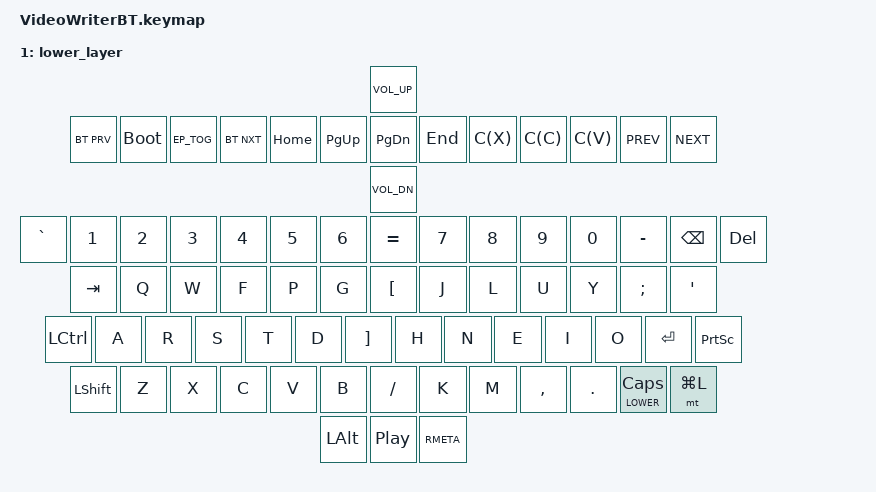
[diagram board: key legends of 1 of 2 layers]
/*
 * Copyright (c) 2020 The ZMK Contributors
 *
 * SPDX-License-Identifier: MIT
 */

#include <behaviors.dtsi>
#include <dt-bindings/zmk/keys.h>
#include <dt-bindings/zmk/bt.h>
#include <dt-bindings/zmk/outputs.h>
#include <dt-bindings/zmk/ext_power.h>

#define DEFAULT 0
#define LOWER   1

/ {
	keymap {
		compatible = "zmk,keymap";

		default_layer {
			// | Esc   | 1 | 2   | 3   | 4  | 5  | 6  | =  | 7    | 8     | 9  | 0  | - | Back Space |
			// | Tab  | Q |  W  | F    | P   | G   | [   | J   | L     | U      | Y   | ;   | ' |
			// |  Left Control|   | A   | R    | S   | T   | D   | ]   | H     | N      | E   | I   | O   | Enter     |
			// | Pg Up | Caps   | Ctrl  | A    | S   | D   | F   | G   | H     | G      | H   | J   | K   | L   | ;    | '     | Enter | Enter  |
			// | Pg Dn | Up     | Shift | Z    | X   | C   | V   | B   | N     | B      | N   | M   | ,   | .   | /    | Shift | Up    |        |
		bindings = <
																			  &kp UP
			&bt BT_PRV &ext_power EP_TOG &bt BT_NXT 	&kp HOME &kp PAGE_UP &kp PAGE_DOWN &kp END 	&kp C(X) &kp C(C) &kp C(V)   &kp LEFT &kp RIGHT	
																	                &kp DOWN 
			&kp ESC   &kp N1    &kp N2   &kp N3    &kp N4    &kp N5    &kp N6    &kp EQUAL  &kp N7    &kp N8    &kp N9   &kp N0    &kp MINUS &kp BSPC   &kp DELETE
			&kp TAB   &kp Q  &kp W &kp F    &kp P  &kp G  		&kp LBKT	 &kp J    &kp L    &kp U    &kp Y    &kp SEMI  &kp APOS
			&kp LCTRL   &kp A     &kp R   &kp S    &kp T    &kp D     &kp RBKT     &kp H     &kp N    &kp E      &kp I     &kp O    &kp ENTER 	&kp PRINTSCREEN
			&kp LSHFT   &kp Z    &kp X    &kp C     &kp V     &kp B     &kp SLASH     &kp K      &kp M     &kp COMMA     &kp DOT    &lt LOWER CAPS		&mt LG(L)
									&kp LALT &kp SPACE      &kp RMETA
	
			>;
		};

		lower_layer {
			// | | | | | | | | | | | | | | | | | | |
			// | | | | | | | | | | | | | | | | | | |
			// | | | | | | | | | | | | | | | | | | |
			// | | | | | | | | | | | | | | | | | | |
			// | | | | | | | | | | | | | | | | | | |
			// | | | | | | | | | | | | | | | | | | |
			bindings = <
																			  &kp C_VOL_UP
			&bt BT_PRV &bootloader EP_TOG &bt BT_NXT 	&kp HOME &kp PAGE_UP &kp PAGE_DOWN &kp END 	&kp C(X) &kp C(C) &kp C(V)   &kp C_PREV &kp C_NEXT
																	                &kp C_VOL_DN 
			&kp GRAVE   &kp N1    &kp N2   &kp N3    &kp N4    &kp N5    &kp N6    &kp EQUAL  &kp N7    &kp N8    &kp N9   &kp N0    &kp MINUS &kp BSPC   &kp DELETE
			&kp TAB   &kp Q  &kp W &kp F    &kp P  &kp G  		&kp LBKT	 &kp J    &kp L    &kp U    &kp Y    &kp SEMI  &kp APOS
			&kp LCTRL   &kp A     &kp R   &kp S    &kp T    &kp D     &kp RBKT     &kp H     &kp N    &kp E      &kp I     &kp O    &kp ENTER 	&kp PRINTSCREEN
			&kp LSHFT   &kp Z    &kp X    &kp C     &kp V     &kp B     &kp SLASH     &kp K      &kp M     &kp COMMA     &kp DOT    &lt LOWER CAPS		&mt LG(L)
									&kp LALT &kp C_PP     &kp RMETA
			
			>;
		};
	};
};
